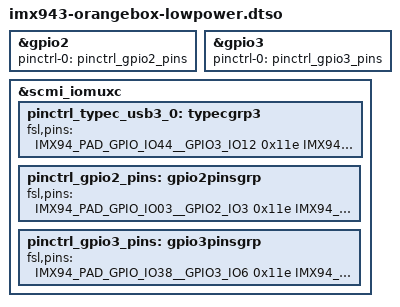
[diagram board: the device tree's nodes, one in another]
// SPDX-License-Identifier: (GPL-2.0+ OR MIT)
/*
 * Copyright 2026 NXP
 */

#include "imx94-pinfunc.h"

/dts-v1/;
/plugin/;

&gpio2 {
	pinctrl-names = "default";
	pinctrl-0 = <&pinctrl_gpio2_pins>;
	
};

&gpio3 {
	pinctrl-names = "default";
	pinctrl-0 = <&pinctrl_gpio3_pins>;
};

&scmi_iomuxc {
    pinctrl_typec_usb3_0: typecgrp3 {
		fsl,pins = <
			IMX94_PAD_GPIO_IO44__GPIO3_IO12		0x11e
			/* The CCM_CLKO1 (output) function will make USB_ID not work */
			IMX94_PAD_CCM_CLKO1__GPIO4_IO0		0x31e
		>;
	};

	pinctrl_gpio2_pins: gpio2pinsgrp {
		fsl,pins = <
			IMX94_PAD_GPIO_IO03__GPIO2_IO3		0x11e
			IMX94_PAD_GPIO_IO21__GPIO2_IO21		0x11e
		>;
	};

	pinctrl_gpio3_pins: gpio3pinsgrp {
		fsl,pins = <
			IMX94_PAD_GPIO_IO38__GPIO3_IO6		0x11e
			IMX94_PAD_GPIO_IO39__GPIO3_IO7		0x11e
			IMX94_PAD_GPIO_IO43__GPIO3_IO11		0x11e
			IMX94_PAD_GPIO_IO57__GPIO3_IO25		0x11e
			IMX94_PAD_GPIO_IO54__GPIO3_IO22		0x11e
			IMX94_PAD_GPIO_IO45__GPIO3_IO13		0x11e
			IMX94_PAD_GPIO_IO55__GPIO3_IO23		0x11e
			IMX94_PAD_GPIO_IO48__GPIO3_IO16		0x11e
			IMX94_PAD_GPIO_IO49__GPIO3_IO17		0x11e
			IMX94_PAD_GPIO_IO50__GPIO3_IO18		0x11e
			IMX94_PAD_GPIO_IO51__GPIO3_IO19		0x11e
			IMX94_PAD_GPIO_IO52__GPIO3_IO20		0x11e
			IMX94_PAD_GPIO_IO53__GPIO3_IO21		0x11e
		>;
	};
};
